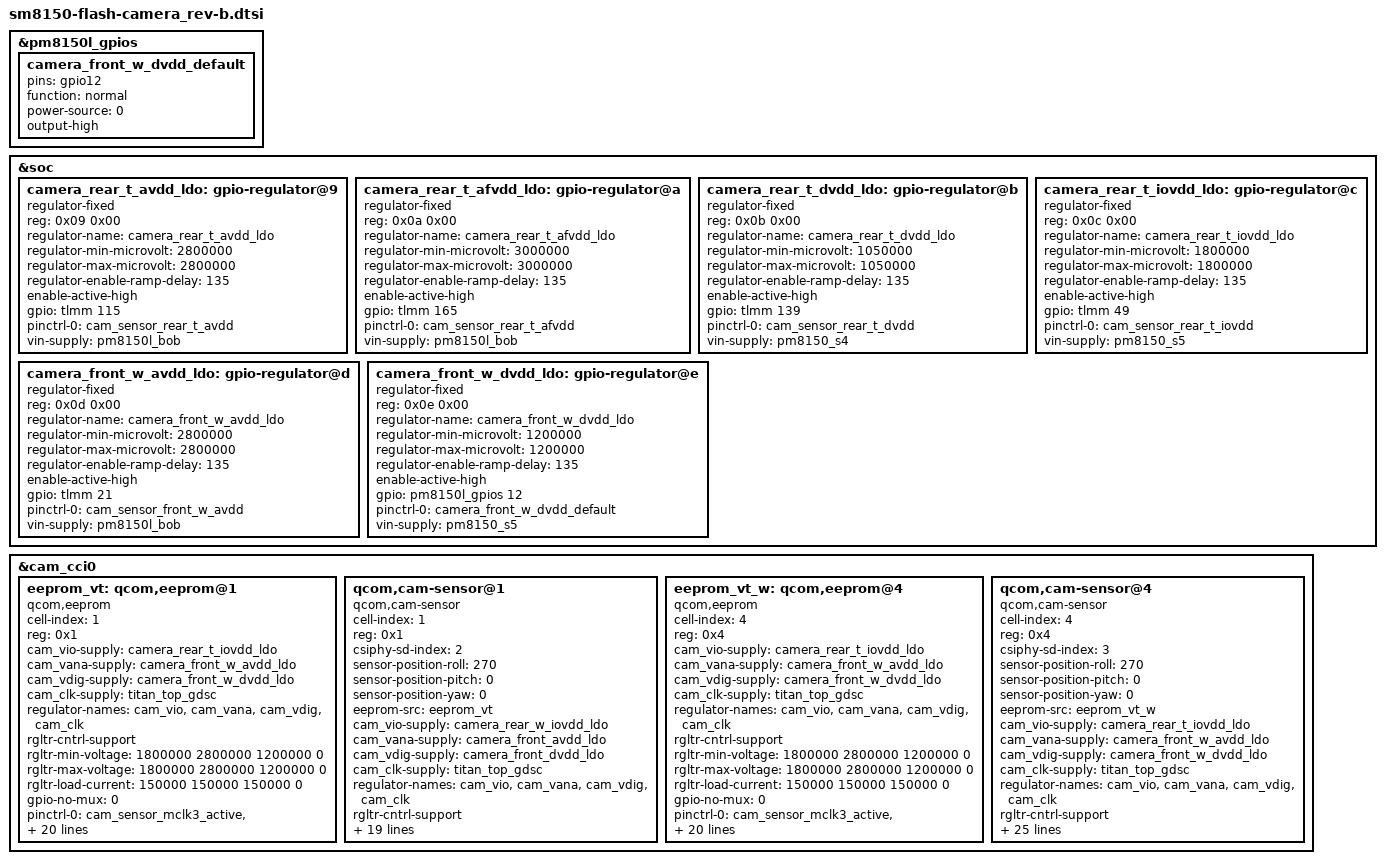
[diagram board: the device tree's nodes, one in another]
/*
 * Copyright (c) 2018, The Linux Foundation. All rights reserved.
 *
 * This program is free software; you can redistribute it and/or modify
 * it under the terms of the GNU General Public License version 2 and
 * only version 2 as published by the Free Software Foundation.
 *
 * This program is distributed in the hope that it will be useful,
 * but WITHOUT ANY WARRANTY; without even the implied warranty of
 * MERCHANTABILITY or FITNESS FOR A PARTICULAR PURPOSE.  See the
 * GNU General Public License for more details.
 */

#include "sm8150-flash-camera_common.dtsi"

&pm8150l_gpios {
	camera_front_w_dvdd_default: camera_front_w_dvdd_default {
		pins = "gpio12";
		function = "normal";
		power-source = <0>;
		output-high;
	};
};

&soc {
	#address-cells = <1>;
	#size-cells = <1>;

	camera_rear_t_avdd_ldo: gpio-regulator@9 {
		compatible = "regulator-fixed";
		reg = <0x09 0x00>;
		regulator-name = "camera_rear_t_avdd_ldo";
		regulator-min-microvolt = <2800000>;
		regulator-max-microvolt = <2800000>;
		regulator-enable-ramp-delay = <135>;
		enable-active-high;
		gpio = <&tlmm 115 0>;
		pinctrl-names = "default";
		pinctrl-0 = <&cam_sensor_rear_t_avdd>;
		vin-supply = <&pm8150l_bob>;
	};

	camera_rear_t_afvdd_ldo: gpio-regulator@a {
		compatible = "regulator-fixed";
		reg = <0x0a 0x00>;
		regulator-name = "camera_rear_t_afvdd_ldo";
		regulator-min-microvolt = <3000000>;
		regulator-max-microvolt = <3000000>;
		regulator-enable-ramp-delay = <135>;
		enable-active-high;
		gpio = <&tlmm 165 0>;
		pinctrl-names = "default";
		pinctrl-0 = <&cam_sensor_rear_t_afvdd>;
		vin-supply = <&pm8150l_bob>;
	};

	camera_rear_t_dvdd_ldo: gpio-regulator@b {
		compatible = "regulator-fixed";
		reg = <0x0b 0x00>;
		regulator-name = "camera_rear_t_dvdd_ldo";
		regulator-min-microvolt = <1050000>;
		regulator-max-microvolt = <1050000>;
		regulator-enable-ramp-delay = <135>;
		enable-active-high;
		gpio = <&tlmm 139 0>;
		pinctrl-names = "default";
		pinctrl-0 = <&cam_sensor_rear_t_dvdd>;
		vin-supply = <&pm8150_s4>;
	};

	camera_rear_t_iovdd_ldo: gpio-regulator@c {
		compatible = "regulator-fixed";
		reg = <0x0c 0x00>;
		regulator-name = "camera_rear_t_iovdd_ldo";
		regulator-min-microvolt = <1800000>;
		regulator-max-microvolt = <1800000>;
		regulator-enable-ramp-delay = <135>;
		enable-active-high;
		gpio = <&tlmm 49 0>;
		pinctrl-names = "default";
		pinctrl-0 = <&cam_sensor_rear_t_iovdd>;
		vin-supply = <&pm8150_s5>;
	};

	camera_front_w_avdd_ldo: gpio-regulator@d {
		compatible = "regulator-fixed";
		reg = <0x0d 0x00>;
		regulator-name = "camera_front_w_avdd_ldo";
		regulator-min-microvolt = <2800000>;
		regulator-max-microvolt = <2800000>;
		regulator-enable-ramp-delay = <135>;
		enable-active-high;
		gpio = <&tlmm 21 0>;
		pinctrl-names = "default";
		pinctrl-0 = <&cam_sensor_front_w_avdd>;
		vin-supply = <&pm8150l_bob>;
	};

	camera_front_w_dvdd_ldo: gpio-regulator@e {
		compatible = "regulator-fixed";
		reg = <0x0e 0x00>;
		regulator-name = "camera_front_w_dvdd_ldo";
		regulator-min-microvolt = <1200000>;
		regulator-max-microvolt = <1200000>;
		regulator-enable-ramp-delay = <135>;
		enable-active-high;
		gpio = <&pm8150l_gpios 12 0>;
		pinctrl-names = "default";
		pinctrl-0 = <&camera_front_w_dvdd_default>;
		vin-supply = <&pm8150_s5>;
	};
};

&cam_cci0 {
	#address-cells = <1>;
	#size-cells = <0>;

	eeprom_vt: qcom,eeprom@1 {
		cell-index = <1>;
		reg = <0x1>;
		compatible = "qcom,eeprom";
		cam_vio-supply = <&camera_rear_t_iovdd_ldo>;
		cam_vana-supply = <&camera_front_w_avdd_ldo>;
		cam_vdig-supply = <&camera_front_w_dvdd_ldo>;
		cam_clk-supply = <&titan_top_gdsc>;
		regulator-names = "cam_vio", "cam_vana", "cam_vdig", "cam_clk";
		rgltr-cntrl-support;
		rgltr-min-voltage = <1800000 2800000 1200000 0>;
		rgltr-max-voltage = <1800000 2800000 1200000 0>;
		rgltr-load-current = <150000 150000 150000 0>;
		gpio-no-mux = <0>;
		pinctrl-names = "cam_default", "cam_suspend";
		pinctrl-0 = <&cam_sensor_mclk3_active
				 &cam_sensor_front_w_active>;
		pinctrl-1 = <&cam_sensor_mclk3_suspend
				 &cam_sensor_front_w_suspend>;
		gpios = <&tlmm 16 0>,
				<&tlmm 25 0>,
				<&tlmm 36 0>,
				<&tlmm 29 0>,
				<&tlmm 138 0>;
		gpio-reset = <1>;
		gpio-standby = <2>;
		gpio-custom1 = <3>;
		gpio-custom2 = <4>;
		gpio-req-tbl-num = <0 1 2 3 4>;
		gpio-req-tbl-flags = <1 0 0 0 0>;
		gpio-req-tbl-label = "VT_W_MCLK",
				     "VT_W_RESET",
				     "VT_W_MIPI_SW_OE_N",
				     "VT_W_MIPI_SEL",
				     "VT_W_MCLK_REQ_2";
		sensor-mode = <0>;
		cci-device = <1>;
		cci-master = <1>;
		status = "ok";
		clocks = <&clock_camcc CAM_CC_MCLK3_CLK>;
		clock-names = "cam_clk";
		clock-cntl-level = "turbo";
		clock-rates = <19200000>;
    };

	qcom,cam-sensor@1 {
		cell-index = <1>;
		compatible = "qcom,cam-sensor";
		reg = <0x1>;
		csiphy-sd-index = <2>;
		sensor-position-roll = <270>;
		sensor-position-pitch = <0>;
		sensor-position-yaw = <0>;
		eeprom-src = <&eeprom_vt>;
		cam_vio-supply = <&camera_rear_w_iovdd_ldo>;
		cam_vana-supply = <&camera_front_avdd_ldo>;
		cam_vdig-supply = <&camera_front_dvdd_ldo>;
		cam_clk-supply = <&titan_top_gdsc>;
		regulator-names = "cam_vio", "cam_vana", "cam_vdig", "cam_clk";
		rgltr-cntrl-support;
		rgltr-min-voltage = <1800000 2800000 1200000 0>;
		rgltr-max-voltage = <1800000 2800000 1200000 0>;
		rgltr-load-current = <150000 150000 150000 0>;
		gpio-no-mux = <0>;
		pinctrl-names = "cam_default", "cam_suspend";
		pinctrl-0 = <&cam_sensor_mclk2_active
				 &cam_sensor_front_active>;
		pinctrl-1 = <&cam_sensor_mclk2_suspend
				 &cam_sensor_front_suspend>;
		gpios = <&tlmm 15 0>,
			<&tlmm 12 0>;
		gpio-reset = <1>;
		gpio-req-tbl-num = <0 1>;
		gpio-req-tbl-flags = <1 0>;
		gpio-req-tbl-label = "VT_MCLK",
					"VT_RESET";
		sensor-mode = <0>;
		cci-device = <1>;
		cci-master = <0>;
		status = "ok";
		clocks = <&clock_camcc CAM_CC_MCLK2_CLK>;
		clock-names = "cam_clk";
		clock-cntl-level = "turbo";
		clock-rates = <19200000>;
	};
	
	eeprom_vt_w: qcom,eeprom@4 {
		cell-index = <4>;
		reg = <0x4>;
		compatible = "qcom,eeprom";
		cam_vio-supply = <&camera_rear_t_iovdd_ldo>;
		cam_vana-supply = <&camera_front_w_avdd_ldo>;
		cam_vdig-supply = <&camera_front_w_dvdd_ldo>;
		cam_clk-supply = <&titan_top_gdsc>;
		regulator-names = "cam_vio", "cam_vana", "cam_vdig", "cam_clk";
		rgltr-cntrl-support;
		rgltr-min-voltage = <1800000 2800000 1200000 0>;
		rgltr-max-voltage = <1800000 2800000 1200000 0>;
		rgltr-load-current = <150000 150000 150000 0>;
		gpio-no-mux = <0>;
		pinctrl-names = "cam_default", "cam_suspend";
		pinctrl-0 = <&cam_sensor_mclk3_active
				 &cam_sensor_front_w_active>;
		pinctrl-1 = <&cam_sensor_mclk3_suspend
				 &cam_sensor_front_w_suspend>;
		gpios = <&tlmm 16 0>,
				<&tlmm 25 0>,
				<&tlmm 36 0>,
				<&tlmm 29 0>,
				<&tlmm 138 0>;
		gpio-reset = <1>;
		gpio-standby = <2>;
		gpio-custom1 = <3>;
		gpio-custom2 = <4>;
		gpio-req-tbl-num = <0 1 2 3 4>;
		gpio-req-tbl-flags = <1 0 0 0 0>;
		gpio-req-tbl-label = "VT_W_MCLK",
				     "VT_W_RESET",
				     "VT_W_MIPI_SW_OE_N",
				     "VT_W_MIPI_SEL",
				     "VT_W_MCLK_REQ_2";
		sensor-mode = <0>;
		cci-device = <1>;
		cci-master = <1>;
		status = "ok";
		clocks = <&clock_camcc CAM_CC_MCLK3_CLK>;
		clock-names = "cam_clk";
		clock-cntl-level = "turbo";
		clock-rates = <19200000>;
    };

	qcom,cam-sensor@4 {
		cell-index = <4>;
		compatible = "qcom,cam-sensor";
		reg = <0x4>;
		csiphy-sd-index = <3>;
		sensor-position-roll = <270>;
		sensor-position-pitch = <0>;
		sensor-position-yaw = <0>;
		eeprom-src = <&eeprom_vt_w>;
		cam_vio-supply = <&camera_rear_t_iovdd_ldo>;
		cam_vana-supply = <&camera_front_w_avdd_ldo>;
		cam_vdig-supply = <&camera_front_w_dvdd_ldo>;
		cam_clk-supply = <&titan_top_gdsc>;
		regulator-names = "cam_vio", "cam_vana", "cam_vdig", "cam_clk";
		rgltr-cntrl-support;
		rgltr-min-voltage = <1800000 2800000 1200000 0>;
		rgltr-max-voltage = <1800000 2800000 1200000 0>;
		rgltr-load-current = <150000 150000 150000 0>;
		gpio-no-mux = <0>;
		pinctrl-names = "cam_default", "cam_suspend";
		pinctrl-0 = <&cam_sensor_mclk3_active
				 &cam_sensor_front_w_active>;
		pinctrl-1 = <&cam_sensor_mclk3_suspend
				 &cam_sensor_front_w_suspend>;
		gpios = <&tlmm 16 0>,
			<&tlmm 25 0>,
                        <&tlmm 36 0>,
                        <&tlmm 29 0>,
                        <&tlmm 138 0>;
		gpio-reset = <1>;
                gpio-standby = <2>;
                gpio-custom1 = <3>;
                gpio-custom2 = <4>;
		gpio-req-tbl-num = <0 1 2 3 4>;
		gpio-req-tbl-flags = <1 0 0 0 0>;
		gpio-req-tbl-label = "VT_W_MCLK",
					"VT_W_RESET",
                                        "VT_W_MIPI_SW_OE_N",
                                        "VT_W_MIPI_SEL",
                                        "VT_W_MCLK_REQ_2";
		sensor-mode = <0>;
		cci-device = <1>;
		cci-master = <1>;
		status = "ok";
		clocks = <&clock_camcc CAM_CC_MCLK3_CLK>;
		clock-names = "cam_clk";
		clock-cntl-level = "turbo";
		clock-rates = <19200000>;
	};
};
